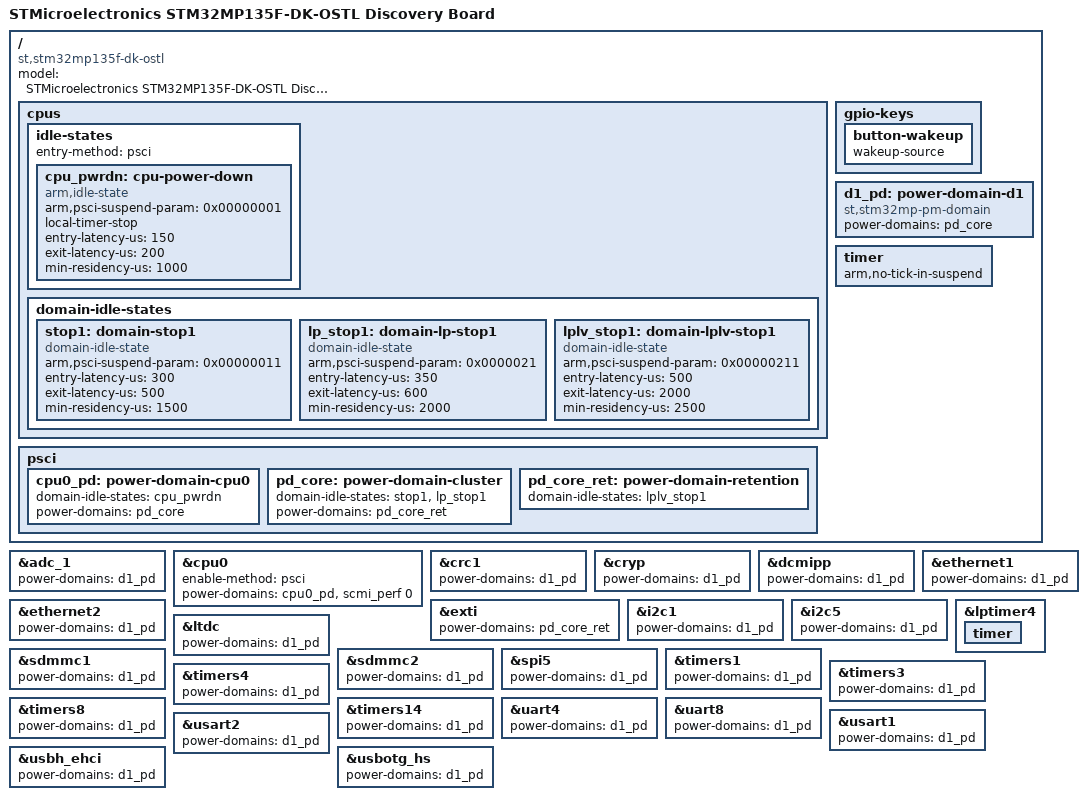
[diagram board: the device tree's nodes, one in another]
// SPDX-License-Identifier: (GPL-2.0-only OR BSD-3-Clause)
/*
 * Copyright (C) STMicroelectronics 2025 - All Rights Reserved
 * Author: Alexandre Torgue <alexandre.torgue@foss.st.com> for STMicroelectronics.
 */

/dts-v1/;

#include "stm32mp135f-dk.dts"

/ {
	model = "STMicroelectronics STM32MP135F-DK-OSTL Discovery Board";
	compatible = "st,stm32mp135f-dk-ostl", "st,stm32mp135f-dk", "st,stm32mp135";

	/* ST PM domain are replaced by PSCI ones */
	/delete-node/ pm_domain;

	cpus {
		idle-states {
			entry-method = "psci";

			cpu_pwrdn: cpu-power-down {
				compatible = "arm,idle-state";
				arm,psci-suspend-param = <0x00000001>;
				local-timer-stop;
				/* TODO: update latency values */
				entry-latency-us = <150>;
				exit-latency-us = <200>;
				min-residency-us = <1000>;
			};
		};

		domain-idle-states {
			stop1: domain-stop1 {
				compatible = "domain-idle-state";
				arm,psci-suspend-param = <0x00000011>;
				/* TODO: update latency values */
				entry-latency-us = <300>;
				exit-latency-us = <500>;
				min-residency-us = <1500>;
			};

			lp_stop1: domain-lp-stop1 {
				compatible = "domain-idle-state";
				arm,psci-suspend-param = <0x0000021>;
				/* TODO: update latency values */
				entry-latency-us = <350>;
				exit-latency-us = <600>;
				min-residency-us = <2000>;
			};

			lplv_stop1: domain-lplv-stop1 {
				compatible = "domain-idle-state";
				arm,psci-suspend-param = <0x00000211>;
				/* TODO: update latency values */
				entry-latency-us = <500>;
				exit-latency-us = <2000>;
				min-residency-us = <2500>;
			};
		};
	};

	gpio-keys {
		button-wakeup {
			wakeup-source;
		};
	};

	d1_pd: power-domain-d1 {
		compatible = "st,stm32mp-pm-domain";
		#power-domain-cells = <0>;
		power-domains = <&pd_core>;
	};

	psci {
		cpu0_pd: power-domain-cpu0 {
			#power-domain-cells = <0>;
			domain-idle-states = <&cpu_pwrdn>;
			power-domains = <&pd_core>;
		};

		pd_core: power-domain-cluster {
			#power-domain-cells = <0>;
			domain-idle-states = <&stop1>, <&lp_stop1>;
			power-domains = <&pd_core_ret>;
		};

		pd_core_ret: power-domain-retention {
			#power-domain-cells = <0>;
			domain-idle-states = <&lplv_stop1>;
		};
	};

	timer {
		/delete-property/ always-on;

		arm,no-tick-in-suspend;
	};
};

&adc_1 {
	power-domains = <&d1_pd>;
};

&cpu0 {
	enable-method = "psci";
	power-domains = <&cpu0_pd>, <&scmi_perf 0>;
	power-domain-names = "psci", "perf";
};

&crc1 {
	power-domains = <&d1_pd>;
};

&cryp {
	power-domains = <&d1_pd>;
};

&dcmipp {
	power-domains = <&d1_pd>;
};

&ethernet1 {
	power-domains = <&d1_pd>;
};

&ethernet2 {
	power-domains = <&d1_pd>;
};

&exti {
	power-domains = <&pd_core_ret>;
};

&i2c1 {
	power-domains = <&d1_pd>;
};

&i2c5 {
	power-domains = <&d1_pd>;
};

/* use lptimer with tick broadcast for suspend mode */
&lptimer4 {
	/delete-property/ power-domains;

	status = "okay";

	timer {
		status = "okay";
	};
};

&ltdc {
	power-domains = <&d1_pd>;
};

&sdmmc1 {
	power-domains = <&d1_pd>;
};

&sdmmc2 {
	power-domains = <&d1_pd>;
};

&spi5 {
	power-domains = <&d1_pd>;
};

&timers1 {
	power-domains = <&d1_pd>;
};

&timers3  {
	power-domains = <&d1_pd>;
};

&timers4  {
	power-domains = <&d1_pd>;
};

&timers8  {
	power-domains = <&d1_pd>;
};

&timers14 {
	power-domains = <&d1_pd>;
};

&uart4 {
	power-domains = <&d1_pd>;
};

&uart8 {
	power-domains = <&d1_pd>;
};

&usart1 {
	power-domains = <&d1_pd>;
};

&usart2 {
	power-domains = <&d1_pd>;
};

&usbh_ehci {
	power-domains = <&d1_pd>;
};

&usbotg_hs {
	power-domains = <&d1_pd>;
};
